# AT32F437 register map
Vendor: Keil; Series: AT32F437; File version: 1.0
CPU: CM4 r0p1, little endian, no MPU, FPU, 4 interrupt priority bits
Registers are 32-bit, read-write, reset 0x0 unless marked. A register's access mark holds for its fields unless they carry their own. Offsets are from the block's base; [hi:lo] are bit positions; {n}, {i} and the like mark numbered series.

## ADCCOM — ADC common area
Base 0x40012300
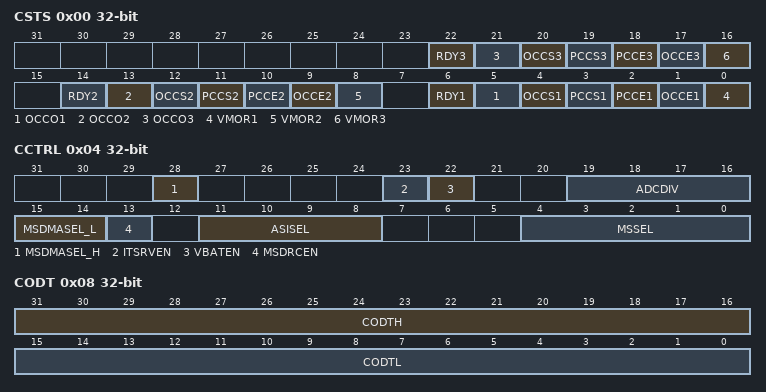
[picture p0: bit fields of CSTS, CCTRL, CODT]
0x00 CSTS ro — Common status register
  [8n-2] RDY{n} (n=1..3) — ADC{n} conversion ready flag
  [8n-3] OCCO{n} (n=1..3) — ADC{n} overrun flag
  [8n-4] OCCS{n} (n=1..3) — ADC{n} ordinary channel conversion start flag
  [8n-5] PCCS{n} (n=1..3) — ADC{n} preempted channel conversion start flag
  [8n-6] PCCE{n} (n=1..3) — ADC{n} preempted channel conversion end flag
  [8n-7] OCCE{n} (n=1..3) — ADC{n} ordinary channel conversion end flag
  [8n-8] VMOR{n} (n=1..3) — ADC{n} voltage monitoring out of range flag
0x04 CCTRL — Common control register
  [28] MSDMASEL_H — MSDMASEL[2] — high bit of ordinary channel DMA transfer mode select for master/slave mode. Combined with MSDMASEL_L to form MSDMASEL[2:0]. 0: No DMA transfer, 1: DMA mode 1, 2: DMA mode 2, 3: DMA mode 3, 4: DMA mode 4, 5: DMA mode 5. 6~7: Unused, do not configure
  [23] ITSRVEN — Internal temperature sensor and VINTRV enable
    0=Disabled (Internal temperature sensor and Vintrv channel disabled); 1=Enabled (Internal temperature sensor and Vintrv channel enabled)
  [22] VBATEN — VBAT enable
    0=Disabled (VBAT channel disabled); 1=Enabled (VBAT channel enabled)
  [19:16] ADCDIV — ADC division: HCLK / (2 + {value}). Cannot be higher than 80Mhz and PCLK2
  [15:14] MSDMASEL_L — MSDMASEL[1:0] — low bits of ordinary channel DMA transfer mode select for master/slave mode. Combined with MSDMASEL_H to form MSDMASEL[2:0]. 0: No DMA transfer, 1: DMA mode 1, 2: DMA mode 2, 3: DMA mode 3, 4: DMA mode 4, 5: DMA mode 5. 6~7: Unused, do not configure
  [13] MSDRCEN — Ordinary channel DMA request continuation enable for master slave mode
    0=Disabled (MSDRC disabled); 1=Enabled (MSDRC enabled)
  [11:8] ASISEL — Adjacent ADC sampling interval select in ordinary shift mode: {value} + 5 * TADCCLK
  [4:0] MSSEL — Master slave mode select
    0=Non-combined mode; 1=CombinedOrdinaryPreempted (Combined ordinary simultaneous+preempted simultaneous modes (single slave)); 2=CombinedOrdinaryAlternate (Combined ordinary simultaneous+alternate preempted trigger modes (single slave)); 5=Preempted simultaneous mode (single slave); 6=Ordinary simultaneous mode (single slave); 7=Ordinary shift mode (single slave); 9=Alternate preempted trigger mode (single slave); 17=CombinedOrdinaryPreemptedDual (Combined ordinary simultaneous+preempted simultaneous modes (dual slaves)); 18=CombinedOrdinaryAlternateDual (Combined ordinary simultaneous+alternate preempted trigger modes (dual slaves)); 21=PreemptedSimultaneousDual (Preempted simultaneous mode (dual slaves)); 22=OrdinarySimultaneousDual (Ordinary simultaneous mode (dual slaves)); 23=OrdinaryShiftDual (Ordinary shift mode (dual slaves)); 25=AlternatePreemptedTriggerDual (Alternate preempted trigger mode (dual slaves))
0x08 CODT ro — Common Ordinary data register
  [31:16] CODTH — Ordinary conversion high halfword data for master slave mode
  [15:0] CODTL — Ordinary conversion low halfword data for master slave mode

## DAC — Digital to analog converter
Base 0x40007400
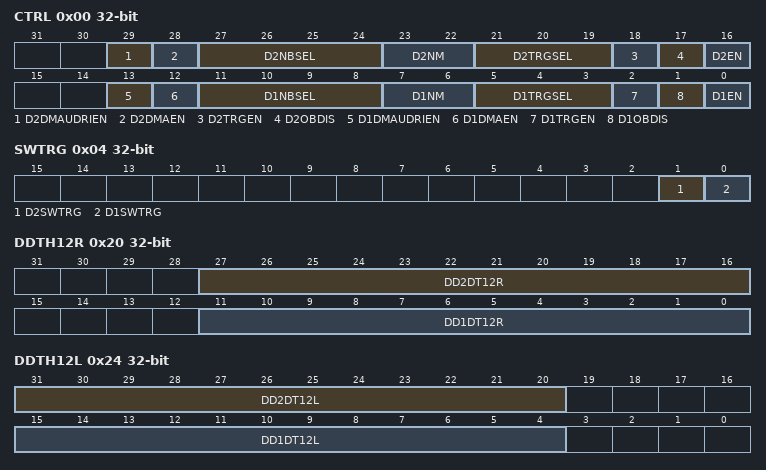
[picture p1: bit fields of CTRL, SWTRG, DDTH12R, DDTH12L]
0x00 CTRL — Control register (DAC_CTRL)
  [29] D2DMAUDRIEN — DAC2 DMA underrun interrupt enable
  [28] D2DMAEN — DAC2 DMA enable
  [27:24] D2NBSEL — DAC2 mask/amplitude selector
  [23:22] D2NM — DAC2 noise/triangle wave generation enable
  [21:19] D2TRGSEL — DAC2 trigger selection
  [18] D2TRGEN — DAC2 trigger enable
  [17] D2OBDIS — DAC2 output buffer disable
  [16] D2EN — DAC2 enable
  [13] D1DMAUDRIEN — DAC1 DMA underrun interrupt enable
  [12] D1DMAEN — DAC1 DMA enable
  [11:8] D1NBSEL — DAC1 mask/amplitude selector
  [7:6] D1NM — DAC1 noise/triangle wave generation enable
  [5:3] D1TRGSEL — DAC1 trigger selection
  [2] D1TRGEN — DAC1 trigger enable
  [1] D1OBDIS — DAC1 output buffer disable
  [0] D1EN — DAC1 enable
0x04 SWTRG wo — DAC software trigger register(DAC_SWTRIGR)
  [1] D2SWTRG — DAC2 software trigger
  [0] D1SWTRG — DAC1 software trigger
0x08 D1DTH12R — DAC1 12-bit right-aligned data holding register(DAC_D1DTH12R)
  [11:0] D1DT12R — DAC1 12-bit right-aligned data
0x0C D1DTH12L — DAC1 12-bit left aligned data holding register (DAC_D1DTH12L)
  [15:4] D1DT12L — DAC1 12-bit left-aligned data
0x10 D1DTH8R — DAC1 8-bit right aligned data holding register (DAC_D1DTH8R)
  [7:0] D1DT8R — DAC1 8-bit right-aligned data
0x14 D2DTH12R — DAC2 12-bit right aligned data holding register (DAC_D2DTH12R)
  [11:0] D2DT12R — DAC2 12-bit right-aligned data
0x18 D2DTH12L — DAC2 12-bit left aligned data holding register (DAC_D2DTH12L)
  [15:4] D2DT12L — DAC2 12-bit left-aligned data
0x1C D2DTH8R — DAC2 8-bit right-aligned data holding register (DAC_D2DTH8R)
  [7:0] D2DT8R — DAC2 8-bit right-aligned data
0x20 DDTH12R — Dual DAC 12-bit right-aligned data holding register (DAC_DDTH12R), Bits 31:28 Reserved, Bits 15:12 Reserved
  [27:16] DD2DT12R — DAC2 12-bit right-aligned data
  [11:0] DD1DT12R — DAC1 12-bit right-aligned data
0x24 DDTH12L — DUAL DAC 12-bit left aligned data holding register (DAC_DDTH12L), Bits 19:16 Reserved, Bits 3:0 Reserved
  [31:20] DD2DT12L — DAC2 12-bit right-aligned data
  [15:4] DD1DT12L — DAC1 12-bit left-aligned data
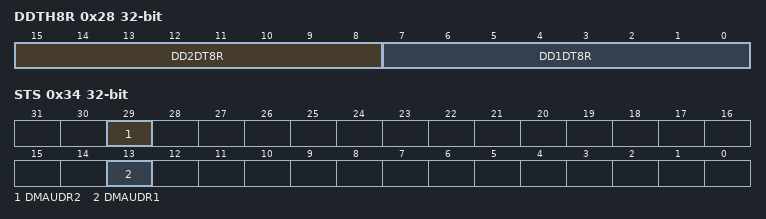
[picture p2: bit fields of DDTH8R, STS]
0x28 DDTH8R — DUAL DAC 8-bit right aligned data holding register (DAC_DDTH8R), Bits 31:16 Reserved
  [15:8] DD2DT8R — DAC2 8-bit right-aligned data
  [7:0] DD1DT8R — DAC1 8-bit right-aligned data
0x2C D1ODT ro — DAC1 data output register (DAC_D1ODT)
  [11:0] D1ODT — DAC1 data output
0x30 D2ODT ro — DAC2 data output register (DAC_D2ODT)
  [11:0] D2ODT — DAC2 data output
0x34 STS — DAC2 status register (DAC_STS)
  [29] DMAUDR2 — DAC2 DMA underrun flag
  [13] DMAUDR1 — DAC1 DMA underrun flag
